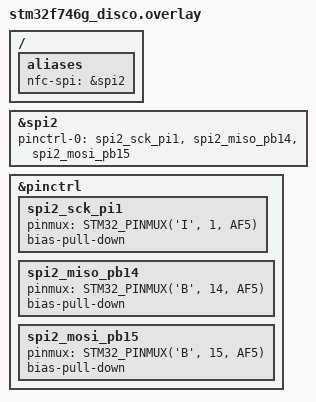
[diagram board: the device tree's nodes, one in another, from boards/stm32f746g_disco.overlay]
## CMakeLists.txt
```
cmake_minimum_required(VERSION 3.20.0)
find_package(Zephyr REQUIRED HINTS $ENV{ZEPHYR_BASE})
project(rfid_2)

file(GLOB app_sources src/*.c)
target_sources(app PRIVATE ${app_sources})
```

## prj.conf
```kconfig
# ================================================
# 1. SOLUTION SD CARD (Configuration "Blindée")
# ================================================
CONFIG_DCACHE=n
CONFIG_DISK_ACCESS=y
CONFIG_FILE_SYSTEM=y
CONFIG_FAT_FILESYSTEM_ELM=y
CONFIG_FS_FATFS_LFN=y
CONFIG_FS_FATFS_CODEPAGE=437
CONFIG_FS_FATFS_MAX_LFN=255

# ================================================
# 2. RESEAU (ADAPTATION MQTT)
# ================================================
CONFIG_NETWORKING=y
CONFIG_NET_SOCKETS=y
CONFIG_POSIX_API=y
CONFIG_NET_IPV4=y

# ### CHANGE : MQTT a besoin de TCP, pas d'UDP ###
CONFIG_NET_TCP=y
CONFIG_NET_UDP=n

# ### CHANGE : Activation de la lib MQTT ###
CONFIG_MQTT_LIB=y

# ### CHANGE : Buffers réseaux (CRITIQUE pour éviter les blocages MQTT) ###
CONFIG_NET_PKT_RX_COUNT=16
CONFIG_NET_PKT_TX_COUNT=16
CONFIG_NET_BUF_RX_COUNT=16
CONFIG_NET_BUF_TX_COUNT=16

# Configuration IP Statique
CONFIG_NET_CONFIG_SETTINGS=y
CONFIG_NET_CONFIG_MY_IPV4_ADDR="192.168.137.10"
CONFIG_NET_CONFIG_MY_IPV4_NETMASK="255.255.255.0"
CONFIG_NET_CONFIG_PEER_IPV4_ADDR="192.168.137.2"

# ================================================
# 3. RANDOM
# ================================================
CONFIG_ENTROPY_GENERATOR=y
CONFIG_TEST_RANDOM_GENERATOR=y

# ================================================
# 4. MEMOIRE
# ================================================
CONFIG_HEAP_MEM_POOL_SIZE=16384 
CONFIG_MAIN_STACK_SIZE=16384
CONFIG_SYSTEM_WORKQUEUE_STACK_SIZE=4096
CONFIG_ISR_STACK_SIZE=2048

# ================================================
# 5. LOGS
# ================================================
CONFIG_LOG=y
CONFIG_SDMMC_LOG_LEVEL_INF=y
CONFIG_FS_LOG_LEVEL_INF=y
CONFIG_MQTT_LOG_LEVEL_INF=y

# ================================================
# 6. ECRAN & LVGL
# ================================================
CONFIG_DISPLAY=y
CONFIG_LVGL=y
CONFIG_LV_Z_MEM_POOL_SIZE=65536
CONFIG_LV_FONT_MONTSERRAT_20=y

# ================================================
# 7. PERIPHERIQUES DE BASE
# ================================================
CONFIG_GPIO=y
CONFIG_SPI=y
CONFIG_I2C=y

# ================================================
# 8. CRYPTO
# ================================================
CONFIG_TINYCRYPT=y
CONFIG_TINYCRYPT_SHA256=y
CONFIG_TINYCRYPT_SHA256_HMAC=y

# ================================================
# 9. CAPTEURS (BME680) - AJOUT POUR METEO
# ================================================
# Active l'API générique des capteurs
CONFIG_SENSOR=y

# Active le driver spécifique Bosch BME680
CONFIG_BME680=y

# Permet d'utiliser printf avec des nombres décimaux (utile pour la température précise)
CONFIG_CBPRINTF_FP_SUPPORT=y
```

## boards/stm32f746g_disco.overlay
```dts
/* app.overlay - Configuration minimale */
/ {
	aliases {
		/* On donne un nom simple pour récupérer le SPI dans le code */
		nfc-spi = &spi2;
	};
};

&spi2 {
	status = "okay";
	/* On configure les pins SCK, MISO, MOSI */
	pinctrl-0 = <&spi2_sck_pi1 &spi2_miso_pb14 &spi2_mosi_pb15>;
	pinctrl-names = "default";
};

&pinctrl {
	spi2_sck_pi1: spi2_sck_pi1 {
		pinmux = <STM32_PINMUX('I', 1, AF5)>;
		bias-pull-down;
	};
	spi2_miso_pb14: spi2_miso_pb14 {
		pinmux = <STM32_PINMUX('B', 14, AF5)>;
		bias-pull-down;
	};
	spi2_mosi_pb15: spi2_mosi_pb15 {
		pinmux = <STM32_PINMUX('B', 15, AF5)>;
		bias-pull-down;
	};
};
```

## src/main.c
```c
#include <zephyr/kernel.h>
#include <zephyr/drivers/gpio.h>
#include <zephyr/drivers/spi.h>
#include <zephyr/logging/log.h>
#include <stdio.h>

#include "pn532.h"
#include "rfid.h"

LOG_MODULE_REGISTER(main, LOG_LEVEL_INF);

/* === GLOBALS === */
static struct spi_config spi_cfg;
static struct spi_cs_control cs_ctrl;

/* Flag pour éviter le spam d'ouverture */
bool barrier_open = false;

/* --- CONFIGURATION DU TAG (Standard NDEF) --- */
const uint8_t capability_container[] = {
    0x00, 0x0F, 0x20, 0x00, 0x54, 0x00, 0xFF, 0x04, 0x06, 0xE1, 0x04, 0x00, 0xFF, 0x00, 0x00
};

const uint8_t ndef_aid[] = { 0xD2, 0x76, 0x00, 0x00, 0x85, 0x01, 0x01 };

/* Mémoire NDEF */
uint8_t ndef_file[256] = { 0x00 };

typedef enum { NONE, CC, NDEF_FILE } tag_file_t;
tag_file_t current_file = NONE;

/* --- LOGIQUE APDU (Gestion des commandes iPhone) --- */
int handle_apdu(uint8_t *rx, uint8_t rx_len, uint8_t *tx, uint8_t *tx_len) {
    uint8_t ins = rx[1];
    uint8_t p1 = rx[2];
    uint8_t p2 = rx[3];
    uint8_t lc = rx[4];
    
    uint8_t sw1 = 0x90, sw2 = 0x00;
    *tx_len = 0;

    switch (ins) {
        case 0xA4: // SELECT FILE
            if (p1 == 0x04) {
                if (lc >= sizeof(ndef_aid) && memcmp(&rx[5], ndef_aid, sizeof(ndef_aid)) == 0) current_file = NONE;
                else { sw1 = 0x6A; sw2 = 0x82; }
            }
            else if (p1 == 0x00) {
                if (rx[5] == 0xE1 && rx[6] == 0x03) current_file = CC;
                else if (rx[5] == 0xE1 && rx[6] == 0x04) current_file = NDEF_FILE;
                else { sw1 = 0x6A; sw2 = 0x82; }
            }
            break;

        case 0xB0: // READ BINARY
            {
                uint16_t offset = (p1 << 8) | p2;
                uint8_t len = rx[4];
                uint8_t *src = NULL;
                uint16_t max_size = 0;

                if (current_file == CC) { src = (uint8_t*)capability_container; max_size = sizeof(capability_container); }
                else if (current_file == NDEF_FILE) { src = ndef_file; max_size = sizeof(ndef_file); }

                if (src != NULL && offset < max_size) {
                    uint8_t copy_len = (offset + len > max_size) ? (max_size - offset) : len;
                    memcpy(tx, src + offset, copy_len);
                    *tx_len = copy_len;
                } else { sw1 = 0x6A; sw2 = 0x82; }
            }
            break;

        case 0xD6: // UPDATE BINARY (L'écriture magique)
            {
                uint16_t offset = (p1 << 8) | p2;
                uint8_t len = lc;

                if (current_file == NDEF_FILE) {
                    if (offset + len <= sizeof(ndef_file)) {
                        memcpy(&ndef_file[offset], &rx[5], len);
                        
                        // Si le paquet est assez gros, on cherche le mot de passe
                        if (len > 2 && !barrier_open) {
                            bool password_found = false;
                            for (int i = 0; i < len; i++) {
                                if ((i + 5 < len) &&
                                    rx[5+i] == 'S' && rx[5+i+1] == 'E' &&
                                    rx[5+i+2] == 'S' && rx[5+i+3] == 'A' &&
                                    rx[5+i+4] == 'M' && rx[5+i+5] == 'E') 
                                {
                                    password_found = true;
                                    break;
                                }
                            }
                            if (password_found) {
                                LOG_INF("\n#######################################");
                                LOG_INF("#   OUVERTURE BARRIERE (IPHONE)       #");
                                LOG_INF("#######################################\n");
                                barrier_open = true;
                                // gpio_pin_set(dev, pin, 1);
                            }
                        }
                    } else { sw1 = 0x6A; sw2 = 0x84; }
                } else { sw1 = 0x69; sw2 = 0x82; }
            }
            break;
        default:
            sw1 = 0x6D; sw2 = 0x00;
            break;
    }

    tx[(*tx_len)++] = sw1;
    tx[(*tx_len)++] = sw2;
    return 0;
}

int main(void)
{
    k_msleep(1000);
    LOG_INF("=== PARKING ACCESS SYSTEM (HIGH RELIABILITY) ===");

    /* --- INITIALISATION HARDWARE --- */
    const struct device *spi_dev = DEVICE_DT_GET(DT_NODELABEL(spi2));
    const struct device *gpio_a = DEVICE_DT_GET(DT_NODELABEL(gpioa));
    const struct device *gpio_i = DEVICE_DT_GET(DT_NODELABEL(gpioi));

    if (!device_is_ready(spi_dev) || !device_is_ready(gpio_a) || !device_is_ready(gpio_i)) return 0;

    // Config SPI PN532
    cs_ctrl.gpio.port = gpio_a; cs_ctrl.gpio.pin = 8; cs_ctrl.gpio.dt_flags = GPIO_ACTIVE_LOW; cs_ctrl.delay = 0;
    spi_cfg.frequency = 500000; spi_cfg.operation = SPI_WORD_SET(8) | SPI_OP_MODE_MASTER;
    spi_cfg.slave = 0;
    pn532_dev_t nfc = { .spi_dev = spi_dev, .spi_cfg = spi_cfg, .cs_gpio = cs_ctrl.gpio, .rst_port = gpio_i, .rst_pin = 2 };

    /* Reset PN532 */
    gpio_pin_configure_dt(&nfc.cs_gpio, GPIO_OUTPUT_INACTIVE);
    gpio_pin_configure(nfc.rst_port, nfc.rst_pin, GPIO_OUTPUT_ACTIVE);
    gpio_pin_set(nfc.rst_port, nfc.rst_pin, 0); k_msleep(100);
    gpio_pin_set(nfc.rst_port, nfc.rst_pin, 1); k_msleep(500);

    if (pn532_init(&nfc) < 0) { LOG_ERR("PN532 Init Failed"); }
    else { pn532_sam_config(&nfc); LOG_INF("PN532 Ready (Slot 2)"); }

    /* Init RC522 */
    MFRC522_Init();
    if (MFRC522_Check_Hardware()) { LOG_INF("RC522 Ready (Slot 1)"); } 
    else { LOG_ERR("RC522 Error"); }

    const uint8_t virtual_uid[3] = { 0x05, 0x05, 0x05 };
    uint8_t rx_buf[255];
    uint8_t tx_buf[255];
    
    // Variables RC522
    uint8_t rc522_uid[10];
    uint8_t rc522_buf[18];
    uint8_t default_key[6] = {0xFF, 0xFF, 0xFF, 0xFF, 0xFF, 0xFF};

    while (1) {
        
        /* ---------------------------------------------------------
         * SLOT 1 : VERIFICATION BADGE PHYSIQUE (RC522)
         * C'est très rapide (< 50ms si pas de badge).
         * --------------------------------------------------------- */
        if (MFRC522_Request(PICC_REQIDL, rc522_buf) == MI_OK) {
            if (MFRC522_Anticoll(rc522_uid) == MI_OK) {
                LOG_INF("[RC522] Badge Physique Detecte");
                MFRC522_SelectTag(rc522_uid);
                
                // Auth et Lecture Bloc 4
                if (MFRC522_Auth(PICC_AUTHENT1A, 4, default_key, rc522_uid) == MI_OK) {
                    if (MFRC522_Read(4, rc522_buf) == MI_OK) {
                        bool match = true;
                        char *pwd = "SESAME";
                        for(int i=0; i<6; i++) if(rc522_buf[i] != pwd[i]) match = false;
                        
                        if(match && !barrier_open) {
                             LOG_INF("\n### OUVERTURE BADGE ###\n");
                             barrier_open = true;
                             // gpio_pin_set...
                        }
                    }
                    MFRC522_StopCrypto1();
                }
                MFRC522_Halt();
                barrier_open = false; 
                
                // Anti-rebond après un succès badge
                k_msleep(1000); 
                continue; // On recommence la boucle
            }
        }

        /* ---------------------------------------------------------
         * SLOT 2 : VERIFICATION IPHONE (PN532)
         * Si un téléphone est détecté, on s'y consacre à 100%
         * --------------------------------------------------------- */
        int ret = pn532_init_as_target(&nfc, virtual_uid);

        if (ret == 0) {
            LOG_INF("[PN532] Smartphone detecte -> Mode Verrouillage");
            
            bool active = true;
            current_file = NONE;
            barrier_open = false;

            while (active) {
                uint8_t rx_len = sizeof(rx_buf);
                
                // === LE SECRET EST ICI ===
                // Timeout de 2500ms (2.5 secondes). 
                // Tant que l'iPhone est là, on attend patiemment sa prochaine commande.
                // Cela couvre largement les animations Apple Pay ou les validations FaceID.
                int r = pn532_tg_get_data(&nfc, rx_buf, &rx_len, 2500); 
                
                if (r > 0) {
                    // Données reçues, on traite
                    uint8_t tx_len = 0;
                    handle_apdu(rx_buf, rx_len, tx_buf, &tx_len);
                    
                    // On répond. Si erreur d'envoi, l'iPhone est parti.
                    if (pn532_tg_set_data(&nfc, tx_buf, tx_len) < 0) active = false;
                }
                else if (r == -ETIMEDOUT) {
                    // Timeout de 2.5s écoulé SANS rien recevoir.
                    // Là, on peut considérer que l'utilisateur est parti ou a abandonné.
                    LOG_INF("[PN532] Timeout long (Session terminee)");
                    active = false;
                }
                else {
                    // Erreur technique
                    active = false;
                }
            }
            // Petite pause pour laisser le champ magnétique retomber
            k_msleep(100);
        }
        else {
            // Pas de téléphone. Reset rapide pour être propre.
            if (ret != -ETIMEDOUT) {
                gpio_pin_set(nfc.rst_port, nfc.rst_pin, 0); k_msleep(10);
                gpio_pin_set(nfc.rst_port, nfc.rst_pin, 1); k_msleep(50);
                pn532_sam_config(&nfc);
            }
        }
        
        // Pause minimale entre les cycles de scan global
        k_msleep(20);
    }
    return 0;
}
```

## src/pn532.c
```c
#include "pn532.h"
#include <zephyr/logging/log.h>

LOG_MODULE_REGISTER(pn532, LOG_LEVEL_INF);

static uint8_t pn532_packetbuffer[64];

static uint8_t reverse_bit_order(uint8_t b) {
    b = (b & 0xF0) >> 4 | (b & 0x0F) << 4;
    b = (b & 0xCC) >> 2 | (b & 0x33) << 2;
    b = (b & 0xAA) >> 1 | (b & 0x55) << 1;
    return b;
}

static int pn532_spi_write_frame(pn532_dev_t *dev, uint8_t *data, uint8_t len) {
    gpio_pin_set_dt(&dev->cs_gpio, 1); 
    k_busy_wait(500); 

    uint8_t cmd = reverse_bit_order(0x01);
    struct spi_buf tx_buf_cmd = { .buf = &cmd, .len = 1 };
    struct spi_buf_set tx_cmd = { .buffers = &tx_buf_cmd, .count = 1 };
    
    if (spi_write(dev->spi_dev, &dev->spi_cfg, &tx_cmd) < 0) {
        gpio_pin_set_dt(&dev->cs_gpio, 0);
        return -EIO;
    }

    for (int i = 0; i < len; i++) {
        uint8_t b = reverse_bit_order(data[i]);
        struct spi_buf tx_buf = { .buf = &b, .len = 1 };
        struct spi_buf_set tx = { .buffers = &tx_buf, .count = 1 };
        spi_write(dev->spi_dev, &dev->spi_cfg, &tx);
    }

    k_busy_wait(500);
    gpio_pin_set_dt(&dev->cs_gpio, 0);
    return 0;
}

static int pn532_wait_ready(pn532_dev_t *dev, int timeout_ms) {
    uint8_t cmd = reverse_bit_order(0x02);
    uint8_t response;
    int slept = 0;

    while (slept < timeout_ms) {
        gpio_pin_set_dt(&dev->cs_gpio, 1);
        k_busy_wait(200);

        struct spi_buf tx_buf = { .buf = &cmd, .len = 1 };
        struct spi_buf_set tx = { .buffers = &tx_buf, .count = 1 };
        spi_write(dev->spi_dev, &dev->spi_cfg, &tx);

        struct spi_buf rx_buf = { .buf = &response, .len = 1 };
        struct spi_buf_set rx = { .buffers = &rx_buf, .count = 1 };
        spi_read(dev->spi_dev, &dev->spi_cfg, &rx);

        gpio_pin_set_dt(&dev->cs_gpio, 0);

        if (reverse_bit_order(response) & 0x01) return 0;

        k_msleep(10); 
        slept += 10;
    }
    return -ETIMEDOUT;
}

static int pn532_read_frame(pn532_dev_t *dev, uint8_t *buff, uint8_t n) {
    uint8_t cmd = reverse_bit_order(0x03);
    uint8_t byte;
    
    gpio_pin_set_dt(&dev->cs_gpio, 1);
    k_busy_wait(500);

    struct spi_buf tx_buf = { .buf = &cmd, .len = 1 };
    struct spi_buf_set tx = { .buffers = &tx_buf, .count = 1 };
    spi_write(dev->spi_dev, &dev->spi_cfg, &tx);

    int timeout = 50; 
    bool synced = false;
    while (timeout > 0) {
        struct spi_buf rx_buf = { .buf = &byte, .len = 1 };
        struct spi_buf_set rx = { .buffers = &rx_buf, .count = 1 };
        spi_read(dev->spi_dev, &dev->spi_cfg, &rx);
        
        if (reverse_bit_order(byte) == 0xFF) {
            synced = true;
            break;
        }
        timeout--;
    }

    if (!synced) {
        gpio_pin_set_dt(&dev->cs_gpio, 0);
        return -EIO; 
    }

    buff[0] = 0x00; buff[1] = 0x00; buff[2] = 0xFF; 

    for(int i=3; i<n; i++) {
        struct spi_buf rx_buf = { .buf = &byte, .len = 1 };
        struct spi_buf_set rx = { .buffers = &rx_buf, .count = 1 };
        spi_read(dev->spi_dev, &dev->spi_cfg, &rx);
        buff[i] = reverse_bit_order(byte);
    }

    gpio_pin_set_dt(&dev->cs_gpio, 0);
    return 0;
}

static int pn532_read_ack(pn532_dev_t *dev) {
    uint8_t ack_buff[6];
    if (pn532_wait_ready(dev, 200) < 0) return -ETIMEDOUT;
    if (pn532_read_frame(dev, ack_buff, 6) < 0) return -EIO;
    if (ack_buff[1] == 0x00 && ack_buff[2] == 0xFF) return 0;
    return -EIO;
}

static int pn532_write_command(pn532_dev_t *dev, uint8_t *header, uint8_t hlen, uint8_t *body, uint8_t blen) {
    uint8_t cmd = 0xD4; 
    pn532_packetbuffer[0] = 0x00; pn532_packetbuffer[1] = 0x00; pn532_packetbuffer[2] = 0xFF;
    uint8_t length = hlen + blen + 1;
    pn532_packetbuffer[3] = length; pn532_packetbuffer[4] = (~length + 1);
    pn532_packetbuffer[5] = cmd;
    uint8_t sum = cmd;
    int idx = 6;
    for (int i = 0; i < hlen; i++) { pn532_packetbuffer[idx++] = header[i]; sum += header[i]; }
    for (int i = 0; i < blen; i++) { pn532_packetbuffer[idx++] = body[i]; sum += body[i]; }
    pn532_packetbuffer[idx++] = (~sum + 1); pn532_packetbuffer[idx++] = 0x00;
    return pn532_spi_write_frame(dev, pn532_packetbuffer, idx);
}

int pn532_init(pn532_dev_t *dev) {
    if (!device_is_ready(dev->spi_dev)) return -ENODEV;
    gpio_pin_configure_dt(&dev->cs_gpio, GPIO_OUTPUT_INACTIVE);
    gpio_pin_configure(dev->rst_port, dev->rst_pin, GPIO_OUTPUT_ACTIVE);
    gpio_pin_set(dev->rst_port, dev->rst_pin, 0); 
    k_msleep(100);
    gpio_pin_set(dev->rst_port, dev->rst_pin, 1);
    k_msleep(500); 
    return 0;
}

int pn532_sam_config(pn532_dev_t *dev) {
    uint8_t cmd[] = {0x14, 0x01, 0x14, 0x01};
    if (pn532_write_command(dev, cmd, sizeof(cmd), NULL, 0) < 0) return -1;
    return pn532_read_ack(dev);
}

int pn532_set_rf_retries(pn532_dev_t *dev, uint8_t max_retries) {
    uint8_t cmd[] = {PN532_COMMAND_RFCONFIGURATION, 0x05, 0xFF, 0x01, max_retries};
    if (pn532_write_command(dev, cmd, sizeof(cmd), NULL, 0) < 0) return -1;
    if (pn532_read_ack(dev) < 0) return -2;
    if (pn532_wait_ready(dev, 100) < 0) return 0;
    uint8_t resp[16];
    pn532_read_frame(dev, resp, 10);
    return 0;
}

int pn532_init_as_target(pn532_dev_t *dev, const uint8_t *nfcid1)
{
    /* Données Historiques (ATS) */
    uint8_t tk[] = { 0x75, 0x77, 0x81, 0x02, 0x80 };

    uint8_t header[64];
    int idx = 0;

    header[idx++] = PN532_COMMAND_TGINITASTARGET;
    
    /* MODE 0x05 pour satisfaire ANDROID et IPHONE (Anti-FeliCa) */
    header[idx++] = 0x05; 

    /* MIFARE Params */
    header[idx++] = 0x04; header[idx++] = 0x00; 
    header[idx++] = nfcid1[0]; header[idx++] = nfcid1[1]; header[idx++] = nfcid1[2]; 
    header[idx++] = 0x20; 

    /* FeliCa Params (Zero) */
    for(int i=0; i<18; i++) header[idx++] = 0x00;

    /* NFCID3t (Zero) */
    for(int i=0; i<10; i++) header[idx++] = 0x00;

    /* General Bytes */
    header[idx++] = 0x00;
    header[idx++] = sizeof(tk);
    for(int i=0; i<sizeof(tk); i++) header[idx++] = tk[i];

    if (pn532_write_command(dev, header, idx, NULL, 0) < 0) return -1;
    if (pn532_read_ack(dev) < 0) return -2;

    /* Attente iPhone/Android */
    if (pn532_wait_ready(dev, 1000) < 0) return -ETIMEDOUT;

    /* Lecture réponse */
    uint8_t resp[64];
    if (pn532_read_frame(dev, resp, sizeof(resp)) < 0) return -3;

    /* Vérification */
    if (resp[6] == 0x7F) return -4; // Erreur syntaxe
    if (resp[6] != 0x8D) return -5; // Mauvaise réponse

    return 0; 
}

int pn532_tg_get_data(pn532_dev_t *dev, uint8_t *buf, uint8_t *len, int timeout_ms)
{
    uint8_t cmd = PN532_COMMAND_TGGETDATA;

    if (pn532_write_command(dev, &cmd, 1, NULL, 0) < 0) return -1;
    if (pn532_read_ack(dev) < 0) return -2;

    if (pn532_wait_ready(dev, timeout_ms) < 0) return 0; 

    uint8_t resp[250]; 
    if (pn532_read_frame(dev, resp, sizeof(resp)) < 0) return -3;

    if (resp[7] != 0x00) return -10 - resp[7]; 
    if (resp[3] < 3) return -5; 
    
    uint8_t data_len = resp[3] - 3;
    if (data_len > *len) data_len = *len;

    for (int i = 0; i < data_len; i++) buf[i] = resp[8 + i];
    *len = data_len;
    return (int)data_len;
}

int pn532_tg_set_data(pn532_dev_t *dev, const uint8_t *data, uint8_t len)
{
    static uint8_t cmd[260]; 
    cmd[0] = 0x8E; // TgSetData
    for(int i=0; i<len; i++) cmd[1+i] = data[i];

    if (pn532_write_command(dev, cmd, len+1, NULL, 0) < 0) return -1;
    if (pn532_read_ack(dev) < 0) return -2;
    
    pn532_wait_ready(dev, 100);
    
    uint8_t dummy[16];
    pn532_read_frame(dev, dummy, 10);
    return 0;
}
```

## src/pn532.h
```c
#ifndef PN532_H
#define PN532_H

#include <zephyr/kernel.h>
#include <zephyr/drivers/gpio.h>
#include <zephyr/drivers/spi.h>

/* Codes de Commande PN532 */
#define PN532_COMMAND_RFCONFIGURATION    0x32
#define PN532_COMMAND_TGINITASTARGET     0x8C
#define PN532_COMMAND_TGGETDATA          0x86
#define PN532_COMMAND_TGSETDATA          0x8E

typedef struct {
    const struct device *spi_dev;
    struct spi_config spi_cfg;
    struct gpio_dt_spec cs_gpio;
    const struct device *rst_port;
    gpio_pin_t rst_pin;
} pn532_dev_t;

/* Prototypes exacts de votre code fonctionnel */
int pn532_init(pn532_dev_t *dev);
int pn532_sam_config(pn532_dev_t *dev);
int pn532_set_rf_retries(pn532_dev_t *dev, uint8_t max_retries);
int pn532_init_as_target(pn532_dev_t *dev, const uint8_t *nfcid1);
int pn532_tg_get_data(pn532_dev_t *dev, uint8_t *buf, uint8_t *len, int timeout_ms);
int pn532_tg_set_data(pn532_dev_t *dev, const uint8_t *data, uint8_t len);

#endif
```

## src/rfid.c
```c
/* src/rfid.c - Driver RC522 Robuste (Soft Reset + Diagnostic) */

#include <zephyr/kernel.h>
#include <zephyr/drivers/spi.h>
#include <zephyr/drivers/gpio.h>
#include <zephyr/logging/log.h>
#include <stdbool.h>
#include "rfid.h"

/* On donne un nom spécifique aux logs de ce fichier */
LOG_MODULE_REGISTER(rfid, LOG_LEVEL_INF);

/* === CONFIGURATION MATERIELLE === */
#define SPI_BUS      DT_NODELABEL(spi2)
#define GPIOA_NODE   DT_NODELABEL(gpioa)
#define CS_PIN       15  /* PA15 pour le Chip Select du RC522 */

static const struct device *z_spi  = NULL;
static const struct device *z_gpio = NULL;

/* Config SPI : 4MHz, MSB First, Master */
static struct spi_config z_spi_cfg = {
    .frequency = 4000000, 
    .operation = SPI_WORD_SET(8) | SPI_TRANSFER_MSB | SPI_OP_MODE_MASTER,
    .slave     = 0,
};

static void cs_select(void)  { gpio_pin_set(z_gpio, CS_PIN, 0); }
static void cs_release(void) { gpio_pin_set(z_gpio, CS_PIN, 1); }

/* --- Primitives SPI --- */
static void Write_MFRC522(uint8_t adr, uint8_t val) {
    uint8_t tx[2] = { (adr << 1) & 0x7E, val };
    struct spi_buf buf = { .buf = tx, .len = 2 };
    struct spi_buf_set set = { .buffers = &buf, .count = 1 };
    
    cs_select();
    spi_write(z_spi, &z_spi_cfg, &set);
    cs_release();
}

static uint8_t Read_MFRC522(uint8_t adr) {
    uint8_t tx[2] = { ((adr << 1) & 0x7E) | 0x80, 0x00 };
    uint8_t rx[2] = { 0, 0 };
    
    struct spi_buf txb = { .buf = tx, .len = 2 };
    struct spi_buf rxb = { .buf = rx, .len = 2 };
    struct spi_buf_set ts = { .buffers = &txb, .count = 1 };
    struct spi_buf_set rs = { .buffers = &rxb, .count = 1 };
    
    cs_select();
    spi_transceive(z_spi, &z_spi_cfg, &ts, &rs);
    cs_release();
    
    return rx[1];
}

static void SetBitMask(uint8_t reg, uint8_t mask) {
    Write_MFRC522(reg, Read_MFRC522(reg) | mask);
}

static void ClearBitMask(uint8_t reg, uint8_t mask) {
    Write_MFRC522(reg, Read_MFRC522(reg) & (~mask));
}

/* --- Initialisation Hardware --- */
static int rc522_hw_init_once(void) {
    if (z_spi) return 0; // Déjà init
    
    z_spi  = DEVICE_DT_GET(SPI_BUS);
    z_gpio = DEVICE_DT_GET(GPIOA_NODE);
    
    if (!device_is_ready(z_spi) || !device_is_ready(z_gpio)) {
        LOG_ERR("RC522: SPI ou GPIO non pret !");
        return -1;
    }
    
    // Config CS
    gpio_pin_configure(z_gpio, CS_PIN, GPIO_OUTPUT_ACTIVE);
    cs_release(); // CS à 1 par défaut
    
    return 0;
}

/* --- DIAGNOSTIC --- */
bool MFRC522_Check_Hardware(void) {
    /* Lecture du registre de version pour voir si la puce répond */
    uint8_t v = Read_MFRC522(VersionReg);
    LOG_INF("RC522 Version Reg: 0x%02X", v);
    
    // 0x92 = Version 2.0, 0x91 = Version 1.0, 0x88 = Clone
    if (v == 0x92 || v == 0x91 || v == 0x88) return true;
    
    return false;
}

/* --- Fonctions Logique --- */
void MFRC522_Reset(void) {
    /* Soft Reset via commande SPI */
    Write_MFRC522(CommandReg, PCD_RESETPHASE);
    k_msleep(50); 
}

void AntennaOn(void) {
    uint8_t temp = Read_MFRC522(TxControlReg);
    if (!(temp & 0x03)) SetBitMask(TxControlReg, 0x03);
}

void CalulateCRC(uint8_t *pIndata, uint8_t len, uint8_t *pOutData) {
    ClearBitMask(DivIrqReg, 0x04);
    SetBitMask(FIFOLevelReg, 0x80);
    for (int i = 0; i < len; i++) Write_MFRC522(FIFODataReg, pIndata[i]);
    Write_MFRC522(CommandReg, PCD_CALCCRC);
    
    int i = 0xFF;
    while(i--) { if (Read_MFRC522(DivIrqReg) & 0x04) break; }
    
    pOutData[0] = Read_MFRC522(CRCResultRegL);
    pOutData[1] = Read_MFRC522(CRCResultRegM);
}

uint8_t MFRC522_ToCard(uint8_t command, uint8_t *sendData, uint8_t sendLen, uint8_t *backData, unsigned short *backLen) {
    uint8_t irqEn = 0x00, waitIRq = 0x00;

    if (command == PCD_AUTHENT) { irqEn = 0x12; waitIRq = 0x10; }
    else if (command == PCD_TRANSCEIVE) { irqEn = 0x77; waitIRq = 0x30; }

    Write_MFRC522(CommIEnReg, irqEn | 0x80);
    ClearBitMask(CommIrqReg, 0x80);
    SetBitMask(FIFOLevelReg, 0x80); 
    Write_MFRC522(CommandReg, PCD_IDLE);

    for (int i = 0; i < sendLen; i++) Write_MFRC522(FIFODataReg, sendData[i]);

    Write_MFRC522(CommandReg, command);
    if (command == PCD_TRANSCEIVE) SetBitMask(BitFramingReg, 0x80);

    int i = 2000;
    while (i--) {
        uint8_t n = Read_MFRC522(CommIrqReg);
        if (n & waitIRq) break; 
        if (n & 0x01) return MI_ERR; 
        k_busy_wait(20); 
    }
    ClearBitMask(BitFramingReg, 0x80);

    if (i == 0) return MI_ERR;
    if (Read_MFRC522(ErrorReg) & 0x1B) return MI_ERR;

    if (backData && backLen) {
        uint8_t n = Read_MFRC522(FIFOLevelReg);
        if (n > *backLen) n = *backLen;
        *backLen = n;
        for (int k = 0; k < n; k++) backData[k] = Read_MFRC522(FIFODataReg);
    }
    return MI_OK;
}

uint8_t MFRC522_Request(uint8_t reqMode, uint8_t *TagType) {
    Write_MFRC522(BitFramingReg, 0x07);
    TagType[0] = reqMode;
    unsigned short len = 2;
    if (MFRC522_ToCard(PCD_TRANSCEIVE, TagType, 1, TagType, &len) != MI_OK || len != 2) return MI_ERR;
    return MI_OK;
}

uint8_t MFRC522_Anticoll(uint8_t *serNum) {
    Write_MFRC522(BitFramingReg, 0x00);
    uint8_t ser[2] = { PICC_ANTICOLL, 0x20 };
    unsigned short len = 5;
    uint8_t buffer[5];
    if (MFRC522_ToCard(PCD_TRANSCEIVE, ser, 2, buffer, &len) != MI_OK) return MI_ERR;
    if (buffer[4] != (buffer[0] ^ buffer[1] ^ buffer[2] ^ buffer[3])) return MI_ERR;
    memcpy(serNum, buffer, 5);
    return MI_OK;
}

uint8_t MFRC522_SelectTag(uint8_t *serNum) {
    uint8_t buf[9];
    buf[0] = PICC_SElECTTAG; buf[1] = 0x70;
    memcpy(&buf[2], serNum, 5);
    CalulateCRC(buf, 7, &buf[7]);
    unsigned short len = 0; 
    uint8_t dump[4]; len=sizeof(dump);
    return (MFRC522_ToCard(PCD_TRANSCEIVE, buf, 9, dump, &len) == MI_OK) ? MI_OK : MI_ERR;
}

uint8_t MFRC522_Auth(uint8_t authMode, uint8_t BlockAddr, uint8_t *Sectorkey, uint8_t *serNum) {
    uint8_t buf[12];
    buf[0] = authMode; buf[1] = BlockAddr;
    memcpy(&buf[2], Sectorkey, 6);
    memcpy(&buf[8], serNum, 4);
    unsigned short len = 0;
    if (MFRC522_ToCard(PCD_AUTHENT, buf, 12, NULL, &len) != MI_OK) return MI_ERR;
    if ((Read_MFRC522(Status2Reg) & 0x08) == 0) return MI_ERR;
    return MI_OK;
}

uint8_t MFRC522_Read(uint8_t blockAddr, uint8_t *recvData) {
    uint8_t buf[4];
    buf[0] = PICC_READ; buf[1] = blockAddr;
    CalulateCRC(buf, 2, &buf[2]);
    unsigned short len = 18; 
    uint8_t buffer[18];
    if (MFRC522_ToCard(PCD_TRANSCEIVE, buf, 4, buffer, &len) != MI_OK) return MI_ERR;
    if (len >= 16) {
        memcpy(recvData, buffer, 16);
        return MI_OK;
    }
    return MI_ERR;
}

uint8_t MFRC522_Write(uint8_t blockAddr, uint8_t *writeData) {
    uint8_t buf[4] = { PICC_WRITE, blockAddr, 0, 0 };
    CalulateCRC(buf, 2, &buf[2]);
    unsigned short len = 0;
    uint8_t ack[4]; len=sizeof(ack);
    if (MFRC522_ToCard(PCD_TRANSCEIVE, buf, 4, ack, &len) != MI_OK) return MI_ERR;
    
    uint8_t frame[18];
    memcpy(frame, writeData, 16);
    CalulateCRC(frame, 16, &frame[16]);
    len=sizeof(ack);
    return MFRC522_ToCard(PCD_TRANSCEIVE, frame, 18, ack, &len);
}

void MFRC522_Halt(void) {
    uint8_t buf[4] = { PICC_HALT, 0 };
    CalulateCRC(buf, 2, &buf[2]);
    unsigned short len = 0;
    MFRC522_ToCard(PCD_TRANSCEIVE, buf, 4, NULL, &len);
}

void MFRC522_StopCrypto1(void) {
    ClearBitMask(Status2Reg, 0x08);
}

void MFRC522_Init(void) {
    if (rc522_hw_init_once() != 0) return;
    
    MFRC522_Reset();
    
    Write_MFRC522(TModeReg, 0x8D);
    Write_MFRC522(TPrescalerReg, 0x3E);
    Write_MFRC522(TReloadRegL, 30); 
    Write_MFRC522(TReloadRegH, 0);
    Write_MFRC522(TxAutoReg, 0x40);
    Write_MFRC522(ModeReg, 0x3D); 
    Write_MFRC522(RFCfgReg, 0x70); // Gain Max
    AntennaOn();
}
```

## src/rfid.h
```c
#ifndef RFID_H
#define RFID_H

#include <stdint.h>
#include <stdbool.h> /* <--- AJOUT NECESSAIRE POUR le type 'bool' */

/* Codes de retour */
#define MI_OK       0
#define MI_NOTAGERR 1
#define MI_ERR      2

/* Commandes MFRC522 */
#define PCD_IDLE              0x00
#define PCD_AUTHENT           0x0E
#define PCD_RECEIVE           0x08
#define PCD_TRANSMIT          0x04
#define PCD_TRANSCEIVE        0x0C
#define PCD_RESETPHASE        0x0F
#define PCD_CALCCRC           0x03

/* Commandes MIFARE */
#define PICC_REQIDL           0x26
#define PICC_REQALL           0x52
#define PICC_ANTICOLL         0x93
#define PICC_SElECTTAG        0x93
#define PICC_AUTHENT1A        0x60
#define PICC_AUTHENT1B        0x61
#define PICC_READ             0x30
#define PICC_WRITE            0xA0
#define PICC_DECREMENT        0xC0
#define PICC_INCREMENT        0xC1
#define PICC_RESTORE          0xC2
#define PICC_TRANSFER         0xB0
#define PICC_HALT             0x50

/* Registres MFRC522 */
#define     Reserved00            0x00
#define     CommandReg            0x01
#define     CommIEnReg            0x02
#define     DivlEnReg             0x03
#define     CommIrqReg            0x04
#define     DivIrqReg             0x05
#define     ErrorReg              0x06
#define     Status1Reg            0x07
#define     Status2Reg            0x08
#define     FIFODataReg           0x09
#define     FIFOLevelReg          0x0A
#define     WaterLevelReg         0x0B
#define     ControlReg            0x0C
#define     BitFramingReg         0x0D
#define     CollReg               0x0E
#define     Reserved01            0x0F
#define     Reserved10            0x10
#define     ModeReg               0x11
#define     TxModeReg             0x12
#define     RxModeReg             0x13
#define     TxControlReg          0x14
#define     TxAutoReg             0x15
#define     TxSelReg              0x16
#define     RxSelReg              0x17
#define     RxThresholdReg        0x18
#define     DemodReg              0x19
#define     Reserved11            0x1A
#define     Reserved12            0x1B
#define     MifareReg             0x1C
#define     Reserved13            0x1D
#define     Reserved14            0x1E
#define     SerialSpeedReg        0x1F
#define     Reserved20            0x20
#define     CRCResultRegM         0x21
#define     CRCResultRegL         0x22
#define     Reserved21            0x23
#define     ModWidthReg           0x24
#define     Reserved22            0x25
#define     RFCfgReg              0x26
#define     GsNReg                0x27
#define     CWGsPReg              0x28
#define     ModGsPReg             0x29
#define     TModeReg              0x2A
#define     TPrescalerReg         0x2B
#define     TReloadRegH           0x2C
#define     TReloadRegL           0x2D
#define     TCounterValueRegH     0x2E
#define     TCounterValueRegL     0x2F
#define     Reserved30            0x30
#define     TestSel1Reg           0x31
#define     TestSel2Reg           0x32
#define     TestPinEnReg          0x33
#define     TestPinValueReg       0x34
#define     TestBusReg            0x35
#define     AutoTestReg           0x36
#define     VersionReg            0x37
#define     AnalogTestReg         0x38
#define     TestDAC1Reg           0x39
#define     TestDAC2Reg           0x3A
#define     TestADCReg            0x3B
#define     Reserved31            0x3C
#define     Reserved32            0x3D
#define     Reserved33            0x3E
#define     Reserved34            0x3F

/* API Publique */
void MFRC522_Init(void);
void MFRC522_Reset(void);
void MFRC522_Halt(void);
void MFRC522_StopCrypto1(void);

/* --- AJOUT POUR DIAGNOSTIC --- */
bool MFRC522_Check_Hardware(void);
/* ----------------------------- */

uint8_t MFRC522_Request(uint8_t reqMode, uint8_t *TagType);
uint8_t MFRC522_Anticoll(uint8_t *serNum);
uint8_t MFRC522_SelectTag(uint8_t *serNum);
uint8_t MFRC522_Auth(uint8_t authMode, uint8_t BlockAddr, uint8_t *Sectorkey, uint8_t *serNum);
uint8_t MFRC522_Read(uint8_t blockAddr, uint8_t *recvData);
uint8_t MFRC522_Write(uint8_t blockAddr, uint8_t *writeData);

#endif
```
